# R9A09G057H register map
Vendor: Renesas Electronics; File version: 1.0
Registers are 32-bit, read-write, no defined reset value unless marked. A register's access mark holds for its fields unless they carry their own. Offsets are from the block's base; [hi:lo] are bit positions; lines under a group give offsets from that group; {n}, {i} and the like mark numbered series.

## R_SSI0 — IO define file for ssi.
Base 0x40049C00
Same registers: R_SSI1 0x4004A000, R_SSI2 0x4004A400, R_SSI3 0x4004A800
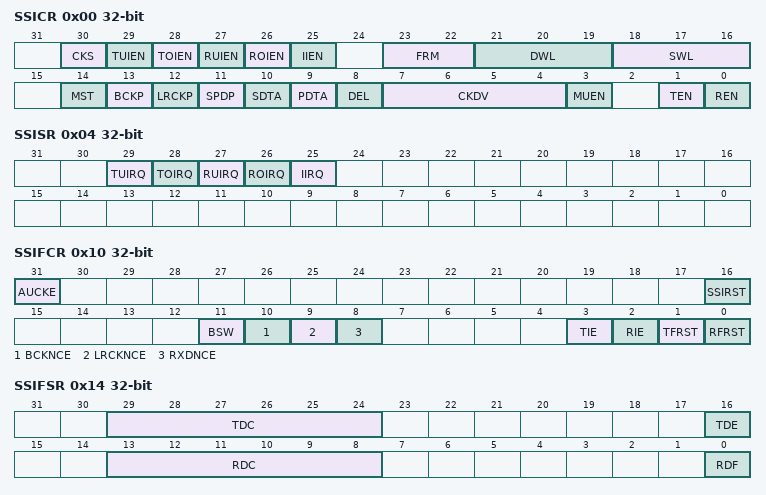
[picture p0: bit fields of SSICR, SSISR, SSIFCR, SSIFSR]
0x00 SSICR
  [30] CKS, [29] TUIEN, [28] TOIEN, [27] RUIEN, [26] ROIEN, [25] IIEN, [23:22] FRM, [21:19] DWL, [18:16] SWL, [14] MST, [13] BCKP, [12] LRCKP, [11] SPDP, [10] SDTA, [9] PDTA, [8] DEL, [7:4] CKDV, [3] MUEN, [1] TEN, [0] REN
0x04 SSISR
  [29] TUIRQ, [28] TOIRQ, [27] RUIRQ, [26] ROIRQ, [25] IIRQ
0x10 SSIFCR
  [31] AUCKE, [16] SSIRST, [11] BSW, [10] BCKNCE, [9] LRCKNCE, [8] RXDNCE, [3] TIE, [2] RIE, [1] TFRST, [0] RFRST
0x14 SSIFSR
  [29:24] TDC ro, [16] TDE, [13:8] RDC ro, [0] RDF
0x18 L 16-bit wo
0x18 LL 8-bit wo
0x18 SSIFTDR wo
0x19 LH 8-bit wo
0x1A H 16-bit wo
0x1A HL 8-bit wo
0x1B HH 8-bit wo
0x1C L_1 16-bit ro
0x1C LL_1 8-bit ro
0x1C SSIFRDR ro
0x1D LH_1 8-bit ro
0x1E H_1 16-bit ro
0x1E HL_1 8-bit ro
0x1F HH_1 8-bit ro
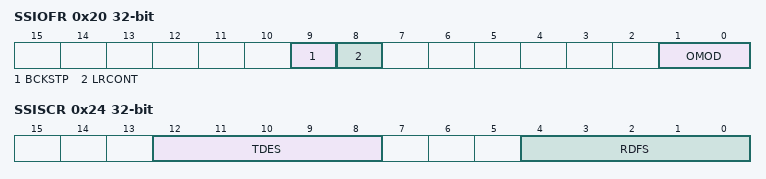
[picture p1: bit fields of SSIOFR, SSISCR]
0x20 SSIOFR
  [9] BCKSTP, [8] LRCONT, [1:0] OMOD
0x24 SSISCR
  [12:8] TDES, [4:0] RDFS

## R_TSU_B0 — IO define file for tsu_b.
Base 0x11000000
Same registers: R_TSU_B1 0x14002000
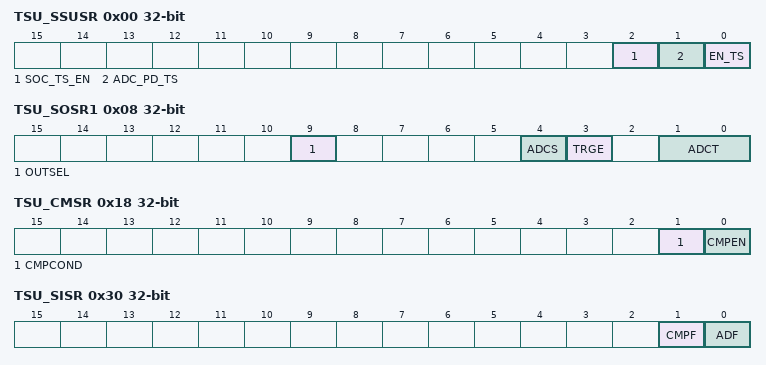
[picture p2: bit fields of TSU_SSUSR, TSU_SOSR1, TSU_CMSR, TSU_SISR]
0x00 TSU_SSUSR
  [2] SOC_TS_EN, [1] ADC_PD_TS, [0] EN_TS
0x04 TSU_STRGR
  [0] ADST wo
0x08 TSU_SOSR1
  [9] OUTSEL, [4] ADCS, [3] TRGE, [1:0] ADCT
0x10 TSU_SCRR ro
  [11:0] OUT12BIT_TS
0x14 TSU_SSR ro
  [0] CONV
0x18 TSU_CMSR
  [1] CMPCOND, [0] CMPEN
0x1C TSU_LLSR
  [11:0] LLIM
0x20 TSU_ULSR
  [11:0] ULIM
0x30 TSU_SISR ro
  [1] CMPF, [0] ADF
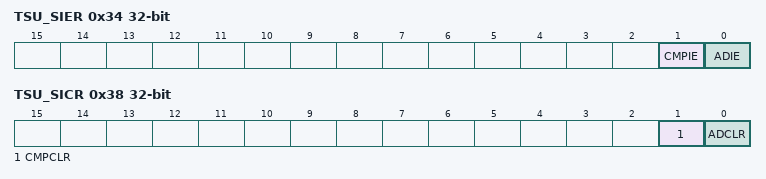
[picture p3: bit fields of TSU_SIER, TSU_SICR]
0x34 TSU_SIER
  [1] CMPIE, [0] ADIE
0x38 TSU_SICR
  [1] CMPCLR wo, [0] ADCLR wo

## R_TZC_SRAMM — IO define file for tzc.
Base 0x10460000
Same registers: R_TZC_XSPI 0x10470000, R_TZC_DDR00 0x13C60000, R_TZC_DDR01 0x13C70000, R_TZC_DDR10 0x13C80000, R_TZC_DDR11 0x13C90000, R_TZC_AXI_RCPU 0x13CA0000, R_TZC_SRAMA 0x13CB0000, R_TZC_PCIE 0x13CC0000
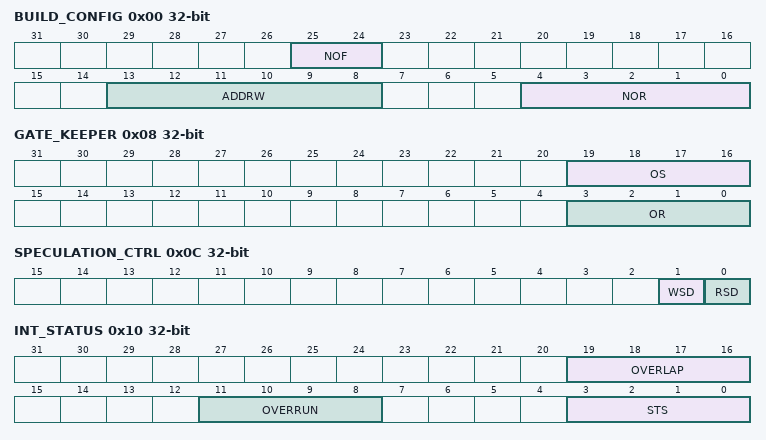
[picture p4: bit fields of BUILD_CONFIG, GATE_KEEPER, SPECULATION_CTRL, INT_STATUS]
0x00 BUILD_CONFIG ro
  [25:24] NOF, [13:8] ADDRW, [4:0] NOR
0x04 ACTION
  [1:0] RV
0x08 GATE_KEEPER
  [19:16] OS, [3:0] OR
0x0C SPECULATION_CTRL
  [1] WSD, [0] RSD
0x10 INT_STATUS ro
  [19:16] OVERLAP, [11:8] OVERRUN, [3:0] STS
0x14 INT_CLEAR wo
  [3:0] CLEAR
{0x20+0x10*i} FAIL_ADDRESS_LOW_{i} ro (i=0..3)
  [31:0] ASL
{0x24+0x10*i} FAIL_ADDRESS_HIGH_{i} ro (i=0..3)
  [0] ASH
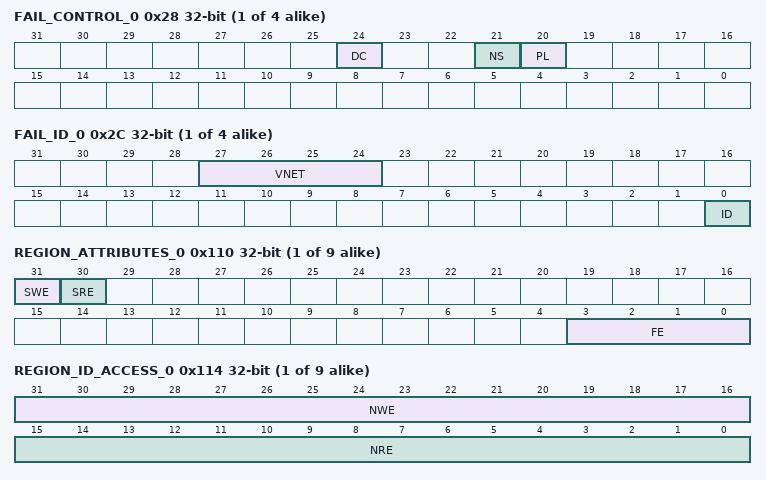
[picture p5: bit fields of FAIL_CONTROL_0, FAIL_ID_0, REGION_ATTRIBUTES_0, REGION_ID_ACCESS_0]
{0x28+0x10*i} FAIL_CONTROL_{i} ro (i=0..3)
  [24] DC, [21] NS, [20] PL
{0x2C+0x10*i} FAIL_ID_{i} ro (i=0..3)
  [27:24] VNET, [0] ID
{0x100+0x20*i} REGION_BASE_LOW_{i} ro (i=0..8)
  [31:12] BAL
0x104 REGION_BASE_HIGH_0 ro
  [0] BAH
{0x108+0x20*i} REGION_TOP_LOW_{i} ro (i=0..8)
  [31:12] TAL
0x10C REGION_TOP_HIGH_0 ro
  [0] TAH
{0x110+0x20*i} REGION_ATTRIBUTES_{i} (i=0..8)
  [31] SWE, [30] SRE, [3:0] FE
{0x114+0x20*i} REGION_ID_ACCESS_{i} (i=0..8)
  [31:16] NWE, [15:0] NRE
{0x104+0x20*i} REGION_BASE_HIGH_{i} ro (i=1..8)
  [{i}:0] BAH
{0x10C+0x20*i} REGION_TOP_HIGH_{i} ro (i=1..8)
  [{i}:0] TAH
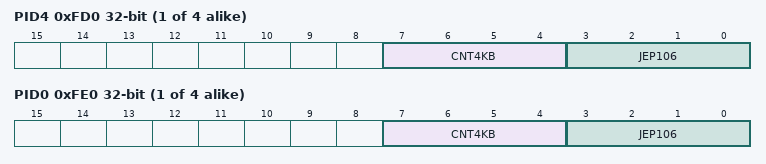
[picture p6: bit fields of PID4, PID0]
{0xFC0+4i} PID{i} ro (i=4..7)
  [7:4] CNT4KB, [3:0] JEP106
{0xFE0+4i} PID{i} ro (i=0..3)
  [7:4] CNT4KB, [3:0] JEP106
{0xFF0+4i} CID{i} ro (i=0..3)
  [7:0] CPI{i}

## R_WDT0 — IO define file for wdt.
Base 0x11C00400
Same registers: R_WDT2 0x13000000, R_WDT3 0x13000400, R_WDT1 0x14400000
0x00 WDT0_WDTRR 8-bit
  [7:0] REFRESH
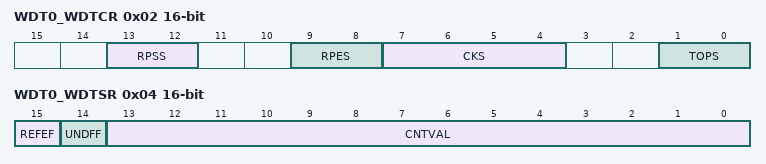
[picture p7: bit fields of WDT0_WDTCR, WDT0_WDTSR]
0x02 WDT0_WDTCR 16-bit
  [13:12] RPSS, [9:8] RPES, [7:4] CKS, [1:0] TOPS
0x04 WDT0_WDTSR 16-bit
  [15] REFEF, [14] UNDFF, [13:0] CNTVAL ro
0x06 WDT0_WDTRCR 8-bit
  [7] RSTIRQS

## R_XSPI0 — IO define file for xspi.
Base 0x11030000
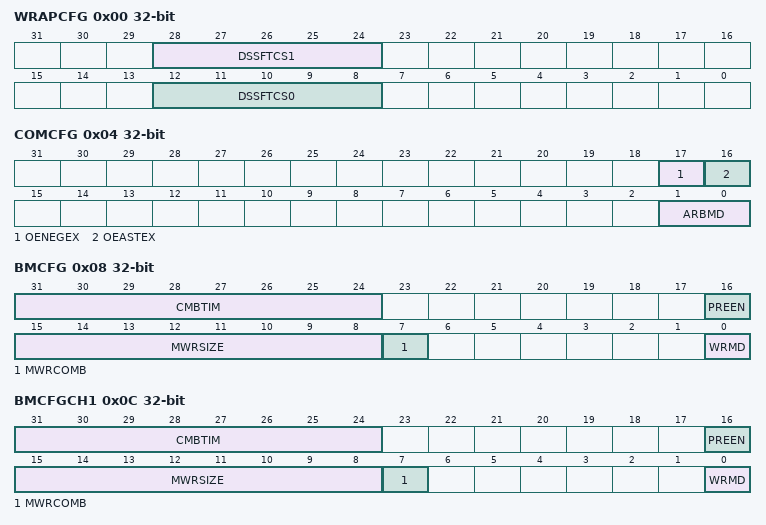
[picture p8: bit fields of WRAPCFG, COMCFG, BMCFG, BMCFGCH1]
0x00 WRAPCFG
  [28:24] DSSFTCS1, [12:8] DSSFTCS0
0x04 COMCFG
  [17] OENEGEX, [16] OEASTEX, [1:0] ARBMD
0x08 BMCFG
  [31:24] CMBTIM, [16] PREEN, [15:8] MWRSIZE, [7] MWRCOMB, [0] WRMD
0x0C BMCFGCH1
  [31:24] CMBTIM, [16] PREEN, [15:8] MWRSIZE, [7] MWRCOMB, [0] WRMD
{0x10+0x10*i} CSa[{i}] (i=0..1) group — CSa register group
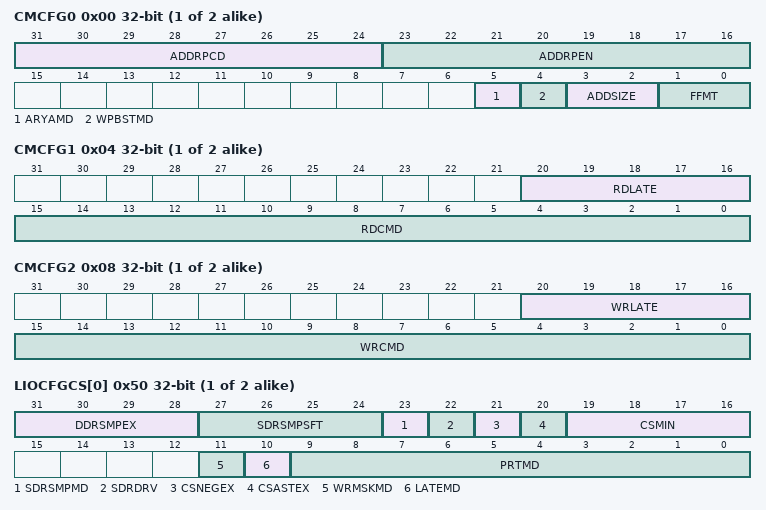
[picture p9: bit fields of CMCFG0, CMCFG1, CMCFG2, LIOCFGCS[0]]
  0x00 CMCFG0
    [31:24] ADDRPCD, [23:16] ADDRPEN, [5] ARYAMD, [4] WPBSTMD, [3:2] ADDSIZE, [1:0] FFMT
  0x04 CMCFG1
    [20:16] RDLATE, [15:0] RDCMD
  0x08 CMCFG2
    [20:16] WRLATE, [15:0] WRCMD
{0x50+4i} LIOCFGCS[{i}] (i=0..1)
  [31:28] DDRSMPEX, [27:24] SDRSMPSFT, [23] SDRSMPMD, [22] SDRDRV, [21] CSNEGEX, [20] CSASTEX, [19:16] CSMIN, [11] WRMSKMD, [10] LATEMD, [9:0] PRTMD
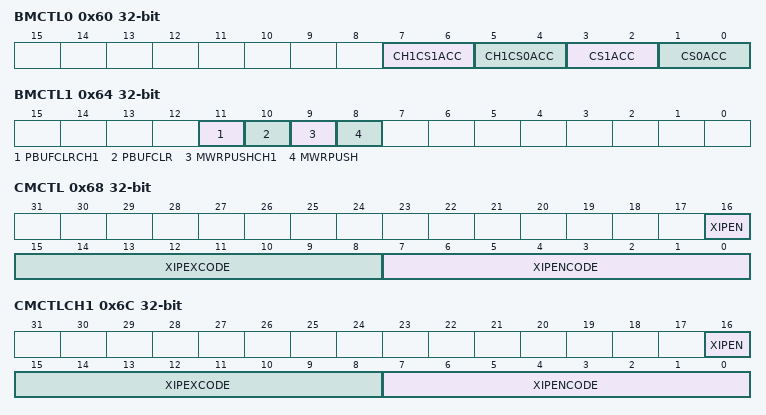
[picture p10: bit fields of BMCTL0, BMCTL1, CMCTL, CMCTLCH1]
0x60 BMCTL0
  [7:6] CH1CS1ACC, [5:4] CH1CS0ACC, [3:2] CS1ACC, [1:0] CS0ACC
0x64 BMCTL1 wo
  [11] PBUFCLRCH1, [10] PBUFCLR, [9] MWRPUSHCH1, [8] MWRPUSH
0x68 CMCTL
  [16] XIPEN, [15:8] XIPEXCODE, [7:0] XIPENCODE
0x6C CMCTLCH1
  [16] XIPEN, [15:8] XIPEXCODE, [7:0] XIPENCODE
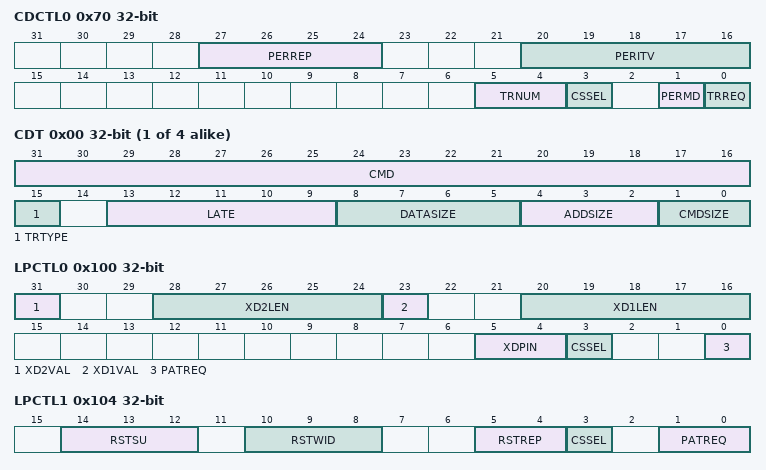
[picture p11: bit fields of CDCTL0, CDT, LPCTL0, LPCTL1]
0x70 CDCTL0
  [27:24] PERREP, [20:16] PERITV, [5:4] TRNUM, [3] CSSEL, [1] PERMD, [0] TRREQ
0x74 CDCTL1
  [31:0] PEREXP
0x78 CDCTL2
  [31:0] PERMSK
{0x80+0x10*i} BUF[{i}] (i=0..3) group — BUF register group
  0x00 CDT
    [31:16] CMD, [15] TRTYPE, [13:9] LATE, [8:5] DATASIZE, [4:2] ADDSIZE, [1:0] CMDSIZE
  0x04 CDA
    [31:0] ADD
  0x08 CDD0
    [31:0] DATA
  0x0C CDD1
    [31:0] DATA
0x100 LPCTL0
  [31] XD2VAL, [28:24] XD2LEN, [23] XD1VAL, [20:16] XD1LEN, [5:4] XDPIN, [3] CSSEL, [0] PATREQ
0x104 LPCTL1
  [14:12] RSTSU, [10:8] RSTWID, [5:4] RSTREP, [3] CSSEL, [1:0] PATREQ
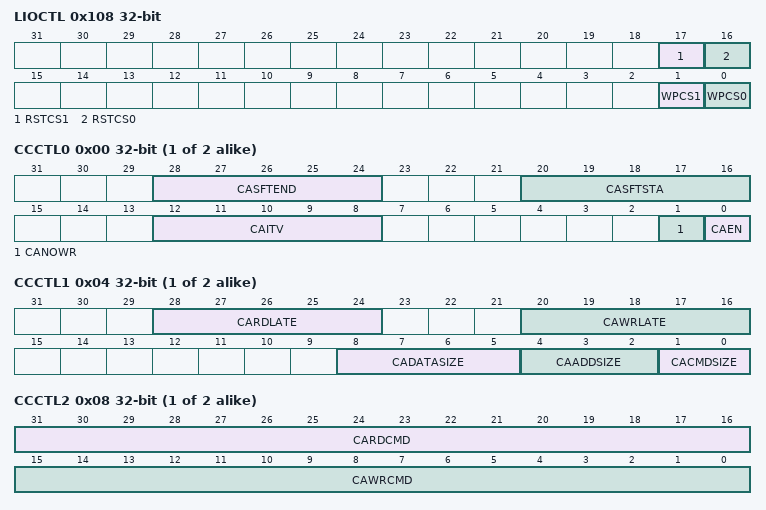
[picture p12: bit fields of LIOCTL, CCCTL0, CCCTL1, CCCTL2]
0x108 LIOCTL
  [17] RSTCS1, [16] RSTCS0, [1] WPCS1, [0] WPCS0
{0x130+0x20*i} CSb[{i}] (i=0..1) group — CSb register group
  0x00 CCCTL0
    [28:24] CASFTEND, [20:16] CASFTSTA, [12:8] CAITV, [1] CANOWR, [0] CAEN
  0x04 CCCTL1
    [28:24] CARDLATE, [20:16] CAWRLATE, [8:5] CADATASIZE, [4:2] CAADDSIZE, [1:0] CACMDSIZE
  0x08 CCCTL2
    [31:16] CARDCMD, [15:0] CAWRCMD
  0x0C CCCTL3
    [31:0] CAADD
  {0x0+4j} CCCTL{j} (j=4..7)
    [31:0] CADATA
0x180 VERSTT ro
  [31:0] VER
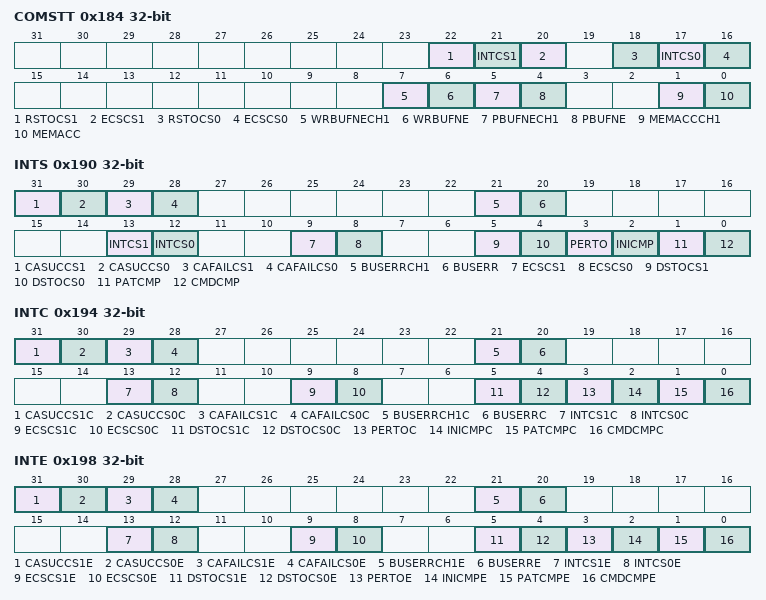
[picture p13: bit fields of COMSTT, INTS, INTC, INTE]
0x184 COMSTT ro
  [22] RSTOCS1, [21] INTCS1, [20] ECSCS1, [18] RSTOCS0, [17] INTCS0, [16] ECSCS0, [7] WRBUFNECH1, [6] WRBUFNE, [5] PBUFNECH1, [4] PBUFNE, [1] MEMACCCH1, [0] MEMACC
{0x188+4i} CASTTCS[{i}] (i=0..1) ro
  [31:0] CASUC
0x190 INTS ro
  [31] CASUCCS1, [30] CASUCCS0, [29] CAFAILCS1, [28] CAFAILCS0, [21] BUSERRCH1, [20] BUSERR, [13] INTCS1, [12] INTCS0, [9] ECSCS1, [8] ECSCS0, [5] DSTOCS1, [4] DSTOCS0, [3] PERTO, [2] INICMP, [1] PATCMP, [0] CMDCMP
0x194 INTC wo
  [31] CASUCCS1C, [30] CASUCCS0C, [29] CAFAILCS1C, [28] CAFAILCS0C, [21] BUSERRCH1C, [20] BUSERRC, [13] INTCS1C, [12] INTCS0C, [9] ECSCS1C, [8] ECSCS0C, [5] DSTOCS1C, [4] DSTOCS0C, [3] PERTOC, [2] INICMPC, [1] PATCMPC, [0] CMDCMPC
0x198 INTE
  [31] CASUCCS1E, [30] CASUCCS0E, [29] CAFAILCS1E, [28] CAFAILCS0E, [21] BUSERRCH1E, [20] BUSERRE, [13] INTCS1E, [12] INTCS0E, [9] ECSCS1E, [8] ECSCS0E, [5] DSTOCS1E, [4] DSTOCS0E, [3] PERTOE, [2] INICMPE, [1] PATCMPE, [0] CMDCMPE
